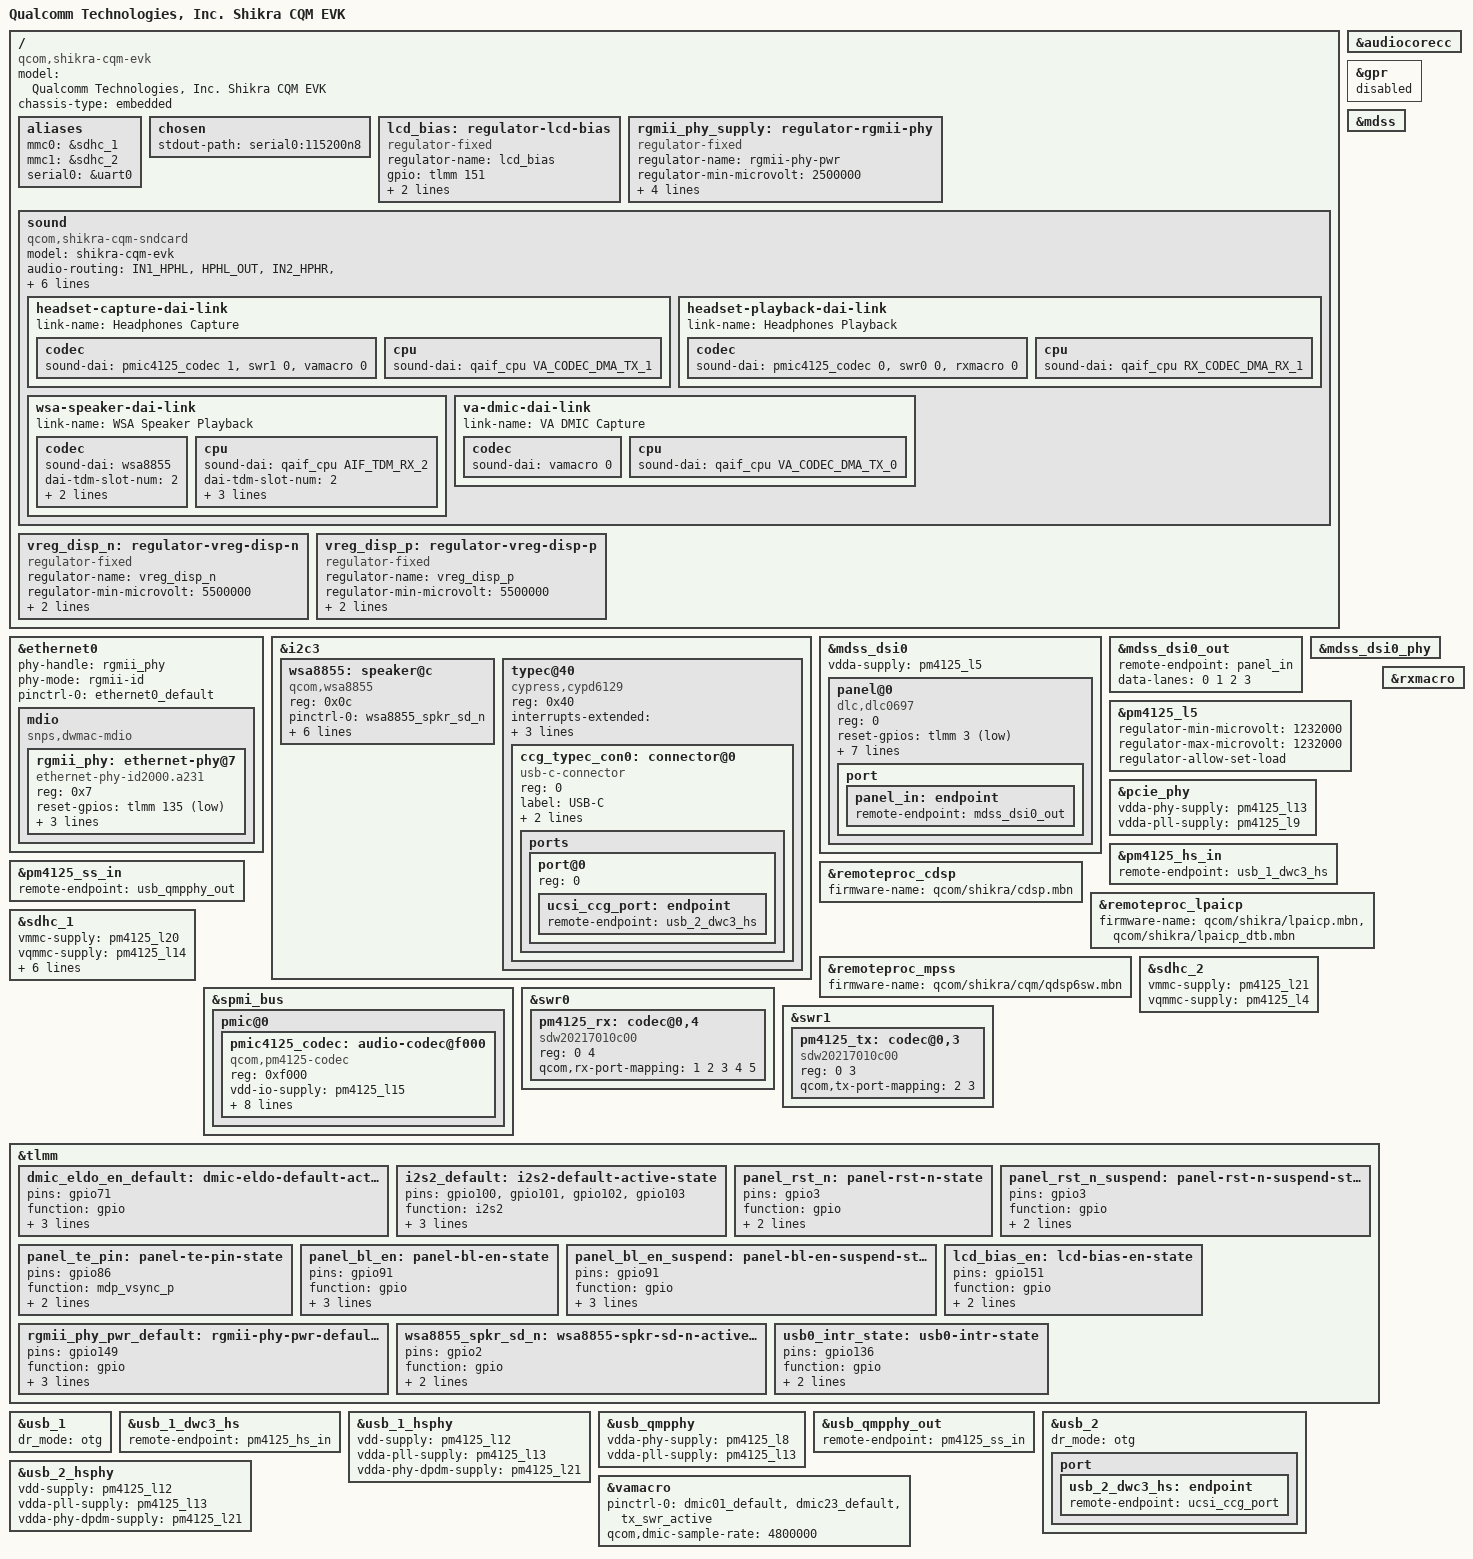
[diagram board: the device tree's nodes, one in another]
// SPDX-License-Identifier: BSD-3-Clause
/*
 * Copyright (c) Qualcomm Technologies, Inc. and/or its subsidiaries.
 */

/dts-v1/;

#include "shikra-cqm-som.dtsi"
#include "shikra-evk.dtsi"
#include <dt-bindings/gpio/gpio.h>

/ {
	model = "Qualcomm Technologies, Inc. Shikra CQM EVK";
	compatible = "qcom,shikra-cqm-evk", "qcom,shikra-cqm-som", "qcom,shikra";
	chassis-type = "embedded";

	aliases {
		mmc0 = &sdhc_1;
		mmc1 = &sdhc_2; /* SDC2 SD card slot */
		serial0 = &uart0;
	};

	chosen {
		stdout-path = "serial0:115200n8";
	};

	lcd_bias: regulator-lcd-bias {
		compatible = "regulator-fixed";
		regulator-name = "lcd_bias";
		gpio = <&tlmm 151 GPIO_ACTIVE_HIGH>;
		enable-active-high;
		pinctrl-0 = <&lcd_bias_en>;
		pinctrl-names = "default";
	};

	rgmii_phy_supply: regulator-rgmii-phy {
		compatible = "regulator-fixed";
		regulator-name = "rgmii-phy-pwr";
		regulator-min-microvolt = <2500000>;
		regulator-max-microvolt = <2500000>;
		gpio = <&tlmm 149 GPIO_ACTIVE_HIGH>;
		enable-active-high;
		pinctrl-0 = <&rgmii_phy_pwr_default>;
		pinctrl-names = "default";
	};

	sound: sound {
		compatible = "qcom,shikra-cqm-sndcard";
		model = "shikra-cqm-evk";

		audio-routing = "IN1_HPHL", "HPHL_OUT",
				"IN2_HPHR", "HPHR_OUT",
				"AMIC1", "MIC BIAS1",
				"AMIC2", "MIC BIAS2",
				"AMIC3", "MIC BIAS3",
				"VA SWR_INPUT0", "ADC1_OUTPUT",
				"VA SWR_INPUT1", "ADC2_OUTPUT",
				"VA DMIC0", "vdd-micb",
				"VA DMIC1", "vdd-micb",
				"VA DMIC2", "vdd-micb",
				"VA DMIC3", "vdd-micb";

		pinctrl-0 = <&i2s2_default>, <&dmic_eldo_en_default>;
		pinctrl-names = "default";

		headset-capture-dai-link {
			link-name = "Headphones Capture";

			codec {
				sound-dai = <&pmic4125_codec 1>,
					    <&swr1 0>,
					    <&vamacro 0>;
			};

			cpu {
				sound-dai = <&qaif_cpu VA_CODEC_DMA_TX_1>;
			};
		};

		headset-playback-dai-link {
			link-name = "Headphones Playback";

			codec {
				sound-dai = <&pmic4125_codec 0>,
					    <&swr0 0>,
					    <&rxmacro 0>;
			};

			cpu {
				sound-dai = <&qaif_cpu RX_CODEC_DMA_RX_1>;
			};
		};

		wsa-speaker-dai-link {
			link-name = "WSA Speaker Playback";

			codec {
				sound-dai = <&wsa8855>;
				dai-tdm-slot-num = <2>;
				dai-tdm-slot-width = <32>;
				dai-tdm-slot-rx-mask = <1 1>;
			};

			cpu {
				sound-dai = <&qaif_cpu AIF_TDM_RX_2>;
				dai-tdm-slot-num = <2>;
				dai-tdm-slot-width = <32>;
				dai-tdm-slot-rx-mask = <1 1>;
				dai-tdm-slot-tx-mask = <1 1>;
			};
		};

		va-dmic-dai-link {
			link-name = "VA DMIC Capture";

			codec {
				sound-dai = <&vamacro 0>;
			};

			cpu {
				sound-dai = <&qaif_cpu VA_CODEC_DMA_TX_0>;
			};
		};
	};

	vreg_disp_n: regulator-vreg-disp-n {
		compatible = "regulator-fixed";
		regulator-name = "vreg_disp_n";
		regulator-min-microvolt = <5500000>;
		regulator-max-microvolt = <5500000>;
		vin-supply = <&lcd_bias>;
	};

	vreg_disp_p: regulator-vreg-disp-p {
		compatible = "regulator-fixed";
		regulator-name = "vreg_disp_p";
		regulator-min-microvolt = <5500000>;
		regulator-max-microvolt = <5500000>;
		vin-supply = <&lcd_bias>;
	};
};

&audiocorecc {
	status = "okay";
};

&ethernet0 {
	phy-handle = <&rgmii_phy>;
	phy-mode = "rgmii-id";

	pinctrl-0 = <&ethernet0_default>;
	pinctrl-names = "default";

	status = "okay";

	mdio {
		compatible = "snps,dwmac-mdio";
		#address-cells = <1>;
		#size-cells = <0>;

		rgmii_phy: ethernet-phy@7 {
			compatible = "ethernet-phy-id2000.a231";
			reg = <0x7>;
			reset-gpios = <&tlmm 135 GPIO_ACTIVE_LOW>;
			reset-assert-us = <10000>;
			reset-deassert-us = <50000>;
			vdda-2p5-supply = <&rgmii_phy_supply>;
		};
	};
};

&gpr {
	status = "disabled";
};

&i2c3 {
	status = "okay";

	wsa8855: speaker@c {
		compatible = "qcom,wsa8855";
		reg = <0x0c>;

		pinctrl-0 = <&wsa8855_spkr_sd_n>;
		pinctrl-names = "default";

		powerdown-gpios = <&tlmm 2 GPIO_ACTIVE_LOW>;
		interrupt-parent = <&tlmm>;
		interrupts = <77 IRQ_TYPE_EDGE_FALLING>;
		vdd-1p8-supply = <&pm4125_l15>;
		vdd-io-supply = <&pm4125_l15>;
		qcom,battery-config = "1s";

		#sound-dai-cells = <0>;
	};
};

&i2c3 {
	status = "okay";

	typec@40 {
		compatible = "cypress,cypd6129";
		reg = <0x40>;
		interrupts-extended = <&tlmm 136 IRQ_TYPE_LEVEL_LOW>;
		pinctrl-0 = <&usb0_intr_state>;
		pinctrl-names = "default";
		wakeup-source;

		#address-cells = <1>;
		#size-cells = <0>;

		ccg_typec_con0: connector@0 {
			compatible = "usb-c-connector";
			reg = <0>;
			label = "USB-C";
			data-role = "dual";
			power-role = "dual";

			ports {
				#address-cells = <1>;
				#size-cells = <0>;

				port@0 {
					reg = <0>;

					ucsi_ccg_port: endpoint {
						remote-endpoint = <&usb_2_dwc3_hs>;
					};
				};
			};
		};
	};
};

&mdss {
	status = "okay";
};

&mdss_dsi0 {
	vdda-supply = <&pm4125_l5>;

	status = "okay";

	panel@0 {
		compatible = "dlc,dlc0697", "ilitek,ili7807s";
		reg = <0>;

		reset-gpios = <&tlmm 3 GPIO_ACTIVE_LOW>;

		vddi-supply = <&pm4125_l15>;
		avdd-supply = <&vreg_disp_p>;
		avee-supply = <&vreg_disp_n>;

		pinctrl-0 = <&panel_rst_n &panel_te_pin &panel_bl_en>;
		pinctrl-1 = <&panel_rst_n_suspend &panel_bl_en_suspend>;
		pinctrl-names = "default", "sleep";

		port {
			panel_in: endpoint {
				remote-endpoint = <&mdss_dsi0_out>;
			};
		};
	};
};

&mdss_dsi0_out {
	remote-endpoint = <&panel_in>;
	data-lanes = <0 1 2 3>;
};

&mdss_dsi0_phy {
	status = "okay";
};

&pm4125_l5 {
	/* DSI VDDA - must be at NOM voltage for PHY PLL lock */
	regulator-min-microvolt = <1232000>;
	regulator-max-microvolt = <1232000>;
	regulator-allow-set-load;
};

&pcie_phy {
	vdda-phy-supply = <&pm4125_l13>;
	vdda-pll-supply = <&pm4125_l9>;

	status = "okay";
};

&pm4125_hs_in {
	remote-endpoint = <&usb_1_dwc3_hs>;
};

&pm4125_ss_in {
	remote-endpoint = <&usb_qmpphy_out>;
};

&remoteproc_cdsp {
	firmware-name = "qcom/shikra/cdsp.mbn";

	status = "okay";
};

&remoteproc_lpaicp {
	firmware-name = "qcom/shikra/lpaicp.mbn",
			"qcom/shikra/lpaicp_dtb.mbn";

	status = "okay";
};

&remoteproc_mpss {
	firmware-name = "qcom/shikra/cqm/qdsp6sw.mbn";

	status = "okay";
};

&rxmacro {
	status = "okay";
};

&sdhc_1 {
	vmmc-supply = <&pm4125_l20>;
	vqmmc-supply = <&pm4125_l14>;

	pinctrl-0 = <&sdc1_state_on>;
	pinctrl-1 = <&sdc1_state_off>;
	pinctrl-names = "default", "sleep";

	non-removable;
	supports-cqe;
	no-sdio;
	no-sd;

	status = "okay";
};

&sdhc_2 {
	vmmc-supply = <&pm4125_l21>;
	vqmmc-supply = <&pm4125_l4>;

	status = "okay";
};

&spmi_bus {
	pmic@0 {
		pmic4125_codec: audio-codec@f000 {
			compatible = "qcom,pm4125-codec";
			reg = <0xf000>;
			vdd-io-supply = <&pm4125_l15>;
			vdd-cp-supply = <&pm4125_s1>;
			vdd-pa-vpos-supply = <&pm4125_s1>;

			vdd-mic-bias-supply = <&pm4125_l22>;
			qcom,micbias1-microvolt = <1800000>;
			qcom,micbias2-microvolt = <1800000>;
			qcom,micbias3-microvolt = <1800000>;

			qcom,rx-device = <&pm4125_rx>;
			qcom,tx-device = <&pm4125_tx>;
			#sound-dai-cells = <1>;

			status = "okay";
		};
	};
};

&swr0 {
	status = "okay";

	pm4125_rx: codec@0,4 {
		compatible = "sdw20217010c00";
		reg = <0 4>;
		qcom,rx-port-mapping = <1 2 3 4 5>;
	};
};

&swr1 {
	status = "okay";

	pm4125_tx: codec@0,3 {
		compatible = "sdw20217010c00";
		reg = <0 3>;
		qcom,tx-port-mapping = <2 3>;
	};
};

&tlmm {
	dmic_eldo_en_default: dmic-eldo-default-active-state {
		pins = "gpio71";
		function = "gpio";
		drive-strength = <8>;
		bias-disable;
		output-high;
	};

	i2s2_default: i2s2-default-active-state {
		pins = "gpio100", "gpio101", "gpio102", "gpio103";
		function = "i2s2";
		drive-strength = <8>;
		output-high;
		bias-disable;
	};

	panel_rst_n: panel-rst-n-state {
		pins = "gpio3";
		function = "gpio";
		drive-strength = <8>;
		bias-disable;
	};

	panel_rst_n_suspend: panel-rst-n-suspend-state {
		pins = "gpio3";
		function = "gpio";
		drive-strength = <2>;
		bias-pull-down;
	};

	panel_te_pin: panel-te-pin-state {
		pins = "gpio86";
		function = "mdp_vsync_p";
		drive-strength = <2>;
		bias-pull-down;
	};

	panel_bl_en: panel-bl-en-state {
		pins = "gpio91";
		function = "gpio";
		drive-strength = <2>;
		bias-disable;
		output-high;
	};

	panel_bl_en_suspend: panel-bl-en-suspend-state {
		pins = "gpio91";
		function = "gpio";
		drive-strength = <2>;
		bias-pull-down;
		output-low;
	};

	lcd_bias_en: lcd-bias-en-state {
		pins = "gpio151";
		function = "gpio";
		drive-strength = <2>;
		bias-disable;
	};

	rgmii_phy_pwr_default: rgmii-phy-pwr-default-state {
		pins = "gpio149";
		function = "gpio";
		drive-strength = <2>;
		bias-disable;
		output-low;
	};

	wsa8855_spkr_sd_n: wsa8855-spkr-sd-n-active-state {
		pins = "gpio2";
		function = "gpio";
		input-disable;
		output-enable;
	};
};

&tlmm {
	usb0_intr_state: usb0-intr-state {
		pins = "gpio136";
		function = "gpio";
		drive-strength = <2>;
		bias-pull-up;
	};
};

&usb_1 {
	dr_mode = "otg";

	status = "okay";
};

&usb_1_dwc3_hs {
	remote-endpoint = <&pm4125_hs_in>;
};

&usb_1_hsphy {
	vdd-supply = <&pm4125_l12>;
	vdda-pll-supply = <&pm4125_l13>;
	vdda-phy-dpdm-supply = <&pm4125_l21>;

	status = "okay";
};

&usb_qmpphy {
	vdda-phy-supply = <&pm4125_l8>;
	vdda-pll-supply = <&pm4125_l13>;

	status = "okay";
};

&usb_qmpphy_out {
	remote-endpoint = <&pm4125_ss_in>;
};

&usb_2 {
	dr_mode = "otg";

	port {
		usb_2_dwc3_hs: endpoint {
			remote-endpoint = <&ucsi_ccg_port>;
		};
	};
};

&usb_2_hsphy {
	vdd-supply = <&pm4125_l12>;
	vdda-pll-supply = <&pm4125_l13>;
	vdda-phy-dpdm-supply = <&pm4125_l21>;

	status = "okay";
};

&vamacro {
	pinctrl-0 = <&dmic01_default>, <&dmic23_default>, <&tx_swr_active>;
	pinctrl-names = "default";

	qcom,dmic-sample-rate = <4800000>;
	status = "okay";
};
